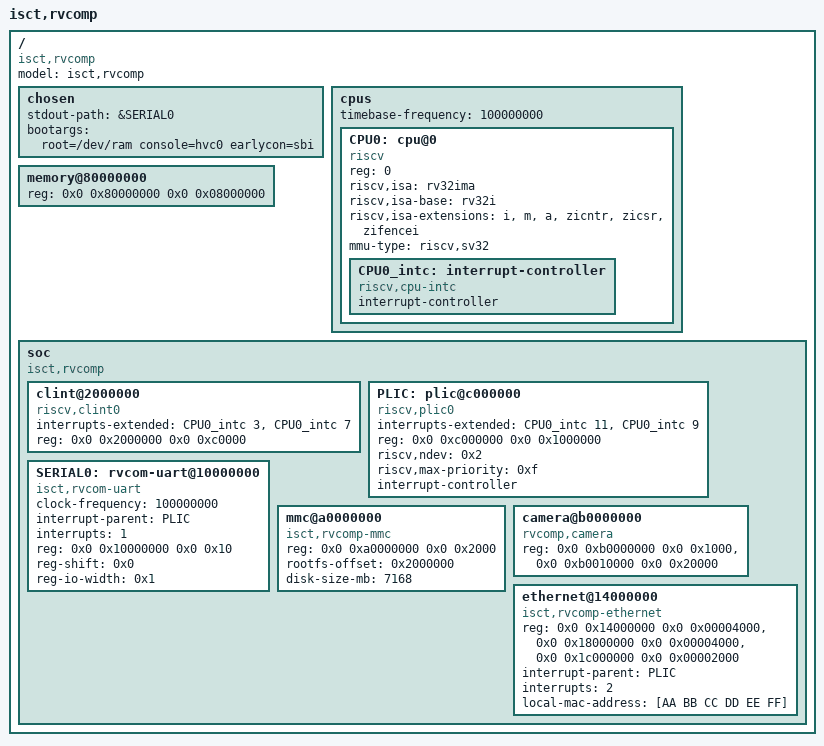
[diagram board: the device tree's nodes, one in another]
// SPDX-License-Identifier: GPL-2.0
// Copyright (c) 2026 Archlab, Science Tokyo
/dts-v1/;

/ {
  #address-cells = <2>;
  #size-cells = <2>;
  compatible = "isct,rvcomp";
  model = "isct,rvcomp";
  chosen {
    stdout-path = &SERIAL0;
    bootargs = "root=/dev/ram console=hvc0 earlycon=sbi";
  };
  cpus {
    #address-cells = <1>;
    #size-cells = <0>;
    timebase-frequency = <100000000>;
    CPU0: cpu@0 {
      device_type = "cpu";
      reg = <0>;
      status = "okay";
      compatible = "riscv";
      riscv,isa = "rv32ima";
      riscv,isa-base = "rv32i";
      riscv,isa-extensions = "i", "m", "a", "zicntr", "zicsr", "zifencei";
      mmu-type = "riscv,sv32";
      CPU0_intc: interrupt-controller {
        #address-cells = <2>;
        #interrupt-cells = <1>;
        interrupt-controller;
        compatible = "riscv,cpu-intc";
      };
    };
  };
  memory@80000000 {
    device_type = "memory";
    reg = <0x0 0x80000000 0x0 0x08000000>; // 128 MiB, nexys4ddr
//    reg = <0x0 0x80000000 0x0 0x10000000>; // 256 MiB, arty_a7
  };
  soc {
    #address-cells = <2>;
    #size-cells = <2>;
    compatible = "isct,rvcomp", "simple-bus";
    ranges;
    clint@2000000 {
      compatible = "riscv,clint0";
      interrupts-extended = <&CPU0_intc 3 &CPU0_intc 7>;
      reg = <0x0 0x2000000 0x0 0xc0000>;
    };
    PLIC: plic@c000000 {
      compatible = "riscv,plic0";
      #address-cells = <2>;
      interrupts-extended = <&CPU0_intc 11 &CPU0_intc 9>;
      reg = <0x0 0xc000000 0x0 0x1000000>;
      riscv,ndev = <0x2>;
      riscv,max-priority = <0xf>;
      #interrupt-cells = <1>;
      interrupt-controller;
    };
    SERIAL0: rvcom-uart@10000000 {
      compatible = "isct,rvcom-uart";
      clock-frequency = <100000000>;
      interrupt-parent = <&PLIC>;
      interrupts = <1>;
      reg = <0x0 0x10000000 0x0 0x10>;
      reg-shift = <0x0>;
      reg-io-width = <0x1>;
    };
    mmc@a0000000 {
      compatible = "isct,rvcomp-mmc";
      reg = <0x0 0xa0000000 0x0 0x2000>;
      rootfs-offset = <0x2000000>;   /* 32 MiB */
      disk-size-mb = <7168>;         /* 7 GiB (8GB MMC) */
      status = "okay";
    };
    camera@b0000000 {
      compatible = "rvcomp,camera";
      reg = <0x0 0xb0000000 0x0 0x1000>,
            <0x0 0xb0010000 0x0 0x20000>;
      reg-names = "csr", "frame";
      status = "okay";
    };
    ethernet@14000000 {
      compatible = "isct,rvcomp-ethernet";
      reg = <0x0 0x14000000 0x0 0x00004000>,
            <0x0 0x18000000 0x0 0x00004000>,
            <0x0 0x1c000000 0x0 0x00002000>;
      reg-names = "csr", "rxbuf", "txbuf";
      interrupt-parent = <&PLIC>;
      interrupts = <2>;
      interrupt-names = "ethernet";
      local-mac-address = [AA BB CC DD EE FF];
      status = "okay";
    };
  };
};
